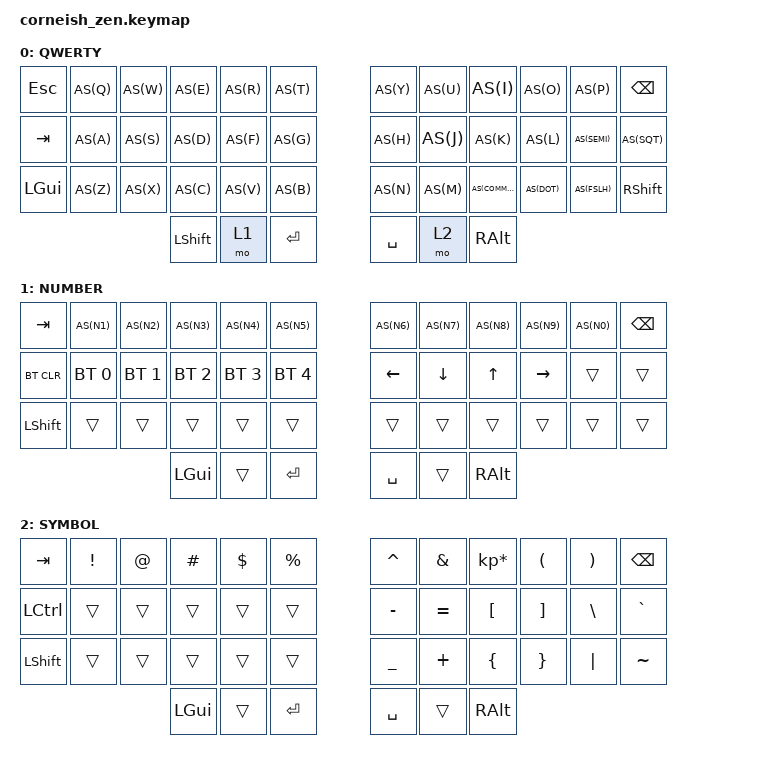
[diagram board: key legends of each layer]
/*
*
* Copyright (c) 2021 Darryl deHaan
* SPDX-License-Identifier: MIT
*
*/

#include <behaviors.dtsi>
#include <dt-bindings/zmk/keys.h>
#include <dt-bindings/zmk/bt.h>

/ {
    chosen {
        zmk,matrix_transform = &default_transform;
        // zmk,matrix_transform = &five_column_transform;
    };
};

#define AS(keycode) &as LS(keycode) keycode

/ {
        behaviors {
            as: auto_shift {
                compatible = "zmk,behavior-hold-tap";
                label = "AUTO_SHIFT";
                #binding-cells = <2>;
                tapping_term_ms = <185>;
                quick_tap_ms = <0>;
                flavor = "tap-preferred";
                bindings = <&kp>, <&kp>;
            };
        };

    
        keymap {
            compatible = "zmk,keymap";
    
            default_layer {
                label = "QWERTY";
    // --------------------------------------------------------------------------------
    // |  TAB |  Q  |  W  |  E  |  R  |  T  |   |  Y  |  U   |  I  |  O  |  P  | BKSP |
    // | CTRL |  A  |  S  |  D  |  F  |  G  |   |  H  |  J   |  K  |  L  |  ;  |  '   |
    // | SHFT |  Z  |  X  |  C  |  V  |  B  |   |  N  |  M   |  ,  |  .  |  /  | ESC  |
    //                    | GUI | LWR | ENT |   | SPC | RSE  | ALT |
                bindings = <
    &kp ESC   AS(Q) AS(W) AS(E) AS(R) AS(T)   AS(Y) AS(U)  AS(I)     AS(O)   AS(P)    &kp BSPC
    &kp TAB AS(A) AS(S) AS(D) AS(F) AS(G)   AS(H) AS(J)  AS(K)     AS(L)   AS(SEMI) AS(SQT)
    &kp LGUI AS(Z) AS(X) AS(C) AS(V) AS(B)   AS(N) AS(M)  AS(COMMA) AS(DOT) AS(FSLH) &kp RSHFT
                   &kp LSHFT &mo 1 &kp RET     &kp SPACE &mo 2 &kp RALT
                >;
            };
    
            lower_layer {
                label = "NUMBER";
    // -----------------------------------------------------------------------------------------
    // |  TAB |  1  |  2  |  3  |  4  |  5  |   |  6  |  7  |  8  |  9  |  0  | BKSP |
    // | BTCLR| BT1 | BT2 | BT3 | BT4 | BT5 |   | LFT | DWN |  UP | RGT |     |      |
    // | SHFT |     |     |     |     |     |   |     |     |     |     |     |      |
    //                    | GUI |     | ENT |   | SPC |     | ALT |
                bindings = <
    &kp TAB    AS(N1)       AS(N2)       AS(N3)       AS(N4)       AS(N5)         AS(N6)   AS(N7)   AS(N8) AS(N9)    AS(N0) &kp BSPC
    &bt BT_CLR &bt BT_SEL 0 &bt BT_SEL 1 &bt BT_SEL 2 &bt BT_SEL 3 &bt BT_SEL 4   &kp LEFT &kp DOWN &kp UP &kp RIGHT &trans &trans
    &kp LSHFT  &trans       &trans       &trans       &trans       &trans         &trans   &trans   &trans &trans    &trans &trans
                                         &kp LGUI     &trans       &kp RET        &kp SPACE  &trans   &kp RALT
                >;
            };
    
            raise_layer {
                label = "SYMBOL";
    // -----------------------------------------------------------------------------------------
    // |  TAB |  !  |  @  |  #  |  $  |  %  |   |  ^  |  &  |  *  |  (  |  )  | BKSP |
    // | CTRL |     |     |     |     |     |   |  -  |  =  |  [  |  ]  |  \  |  `   |
    // | SHFT |     |     |     |     |     |   |  _  |  +  |  {  |  }  | "|" |  ~   |
    //                    | GUI |     | ENT |   | SPC |     | ALT |
                bindings = <
    &kp  TAB  &kp EXCL &kp AT &kp HASH &kp DLLR &kp PRCNT   &kp CARET &kp AMPS  &kp KP_MULTIPLY &kp LPAR &kp RPAR &kp BSPC
    &kp LCTRL &trans   &trans &trans   &trans   &trans      &kp MINUS &kp EQUAL &kp LBKT        &kp RBKT &kp BSLH &kp GRAVE
    &kp LSHFT &trans   &trans &trans   &trans   &trans      &kp UNDER &kp PLUS  &kp LBRC        &kp RBRC &kp PIPE &kp TILDE
                              &kp LGUI &trans   &kp RET     &kp SPACE   &trans    &kp RALT
                >;
            };
        };
    };
